VERSION ""

NS_ :

BS_:

BU_: DCDC OBCharger

BO_ 3221225472 VECTOR__INDEPENDENT_SIG_MSG: 0 Vector__XXX
 SG_ DCDC_Protect_Command : 0|2@0+ (1,0) [0|3] "" Vector__XXX

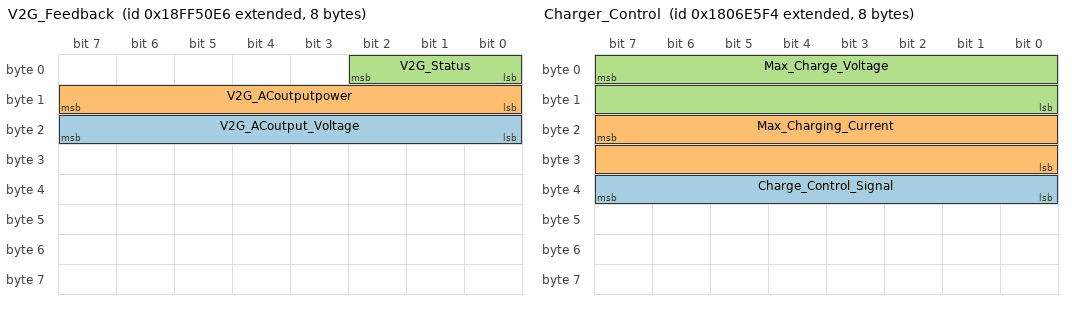
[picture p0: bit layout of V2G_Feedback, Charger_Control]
BO_ 2566869222 V2G_Feedback: 8 OBCharger
 SG_ V2G_ACoutput_Voltage : 23|8@0+ (1,0) [0|255] "V" Vector__XXX
 SG_ V2G_ACoutputpower : 15|8@0+ (0.1,0) [0|25.5] "kw" Vector__XXX
 SG_ V2G_Status : 2|3@0+ (1,0) [0|7] "" Vector__XXX

BO_ 2550588917 V2G_Control: 8 Vector__XXX
 SG_ V2G_Mode : 7|3@0+ (1,0) [0|7] "" Vector__XXX

BO_ 2550173648 DCDC_Control: 8 Vector__XXX
 SG_ DCDC_Control_Command : 1|2@0+ (1,0) [0|3] ""  DCDC

BO_ 2550255759 DCDC_Feedback: 8 DCDC
 SG_ DCDC_Temperature : 63|8@0+ (0.1,0) [0|255] "C" Vector__XXX
 SG_ DCDC_Warm_Temp : 40|1@0+ (1,0) [0|1] "" Vector__XXX
 SG_ DCDC_OverVoltage_outpur : 44|1@0+ (1,0) [0|0] "" Vector__XXX
 SG_ DCDC_OverVoltage_Input : 42|1@0+ (1,0) [0|1] "" Vector__XXX
 SG_ DCDC_Over_Temp : 41|1@0+ (1,0) [0|1] "" Vector__XXX
 SG_ DCDC_LowVoltage_ouptut : 45|1@0+ (1,0) [0|1] "" Vector__XXX
 SG_ DCDC_LowVoltage_input : 43|1@0+ (1,0) [0|1] "" Vector__XXX
 SG_ DCDC_OverCurr_output : 46|1@0+ (1,0) [0|1] "" Vector__XXX
 SG_ DCDC_Ready : 32|1@0+ (1,0) [0|1] "" Vector__XXX
 SG_ DCDC_Status : 33|1@0+ (1,0) [0|1] "" Vector__XXX
 SG_ DCDC_Hard_Fault : 34|1@0+ (1,0) [0|1] "" Vector__XXX
 SG_ DCDC_CAN_error : 35|1@0+ (1,0) [0|255] "" Vector__XXX
 SG_ DCDC_Stop_ERR : 37|1@0+ (1,0) [0|1] "" Vector__XXX
 SG_ DCDC_Fan_control : 36|1@0+ (1,0) [0|1] "" Vector__XXX
 SG_ DCDC_Water_Fan : 38|1@0+ (1,0) [0|1] "" Vector__XXX
 SG_ DCDC_HVIL_ERR : 39|1@0+ (1,0) [0|1] "" Vector__XXX
 SG_ DCDC_Current : 23|16@0+ (0.1,0) [0|65535] "A" Vector__XXX
 SG_ DCDC_Voltage_12V : 7|16@0+ (0.1,0) [0|6553.5] "V" Vector__XXX

BO_ 2550588916 Charger_Control: 8 Vector__XXX
 SG_ Charge_Control_Signal : 39|8@0+ (1,0) [0|0] ""  OBCharger
 SG_ Max_Charging_Current : 23|16@0+ (0.1,0) [0|22.93725] "A"  OBCharger
 SG_ Max_Charge_Voltage : 7|16@0+ (0.1,0) [0|6553.5] "V"  OBCharger

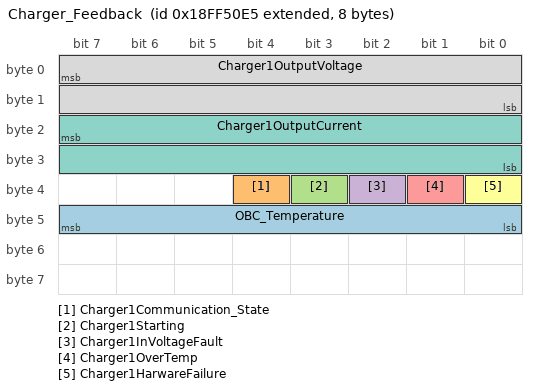
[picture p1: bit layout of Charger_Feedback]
BO_ 2566869221 Charger_Feedback: 8 OBCharger
 SG_ OBC_Temperature : 47|8@0+ (1,0) [0|255] "" Vector__XXX
 SG_ Charger1Communication_State : 36|1@0+ (1,0) [0|1] "" Vector__XXX
 SG_ Charger1Starting : 35|1@0+ (1,0) [0|1] "" Vector__XXX
 SG_ Charger1InVoltageFault : 34|1@0+ (1,0) [0|1] "" Vector__XXX
 SG_ Charger1OverTemp : 33|1@0+ (1,0) [0|1] "" Vector__XXX
 SG_ Charger1HarwareFailure : 32|1@0+ (1,0) [0|1] "" Vector__XXX
 SG_ Charger1OutputCurrent : 23|16@0+ (0.1,0) [0|65.535] "A" Vector__XXX
 SG_ Charger1OutputVoltage : 7|16@0+ (0.1,0) [0|65.535] "V" Vector__XXX

CM_ BO_ 3221225472 "This is a message for not used signals, created by Vector CANdb++ DBC OLE DB Provider.";
BA_DEF_ SG_  "GenSigSendType" ENUM  "Cyclic","OnWrite","OnWriteWithRepetition","OnChange","OnChangeWithRepetition","IfActive","IfActiveWithRepetition","NoSigSendType";
BA_DEF_ SG_  "GenSigILSupport" ENUM  "No","Yes";
BA_DEF_ SG_  "GenSigEVName" STRING ;
BA_DEF_ SG_  "SigType" ENUM  "Default","Range","RangeSigned","ASCII","Discrete","Control","ReferencePGN","DTC","StringDelimiter","StringLength","StringLengthControl";
BA_DEF_ BO_  "VFrameFormat" ENUM  "StandardCAN","ExtendedCAN","reserved","J1939PG";
BA_DEF_ BO_  "GenMsgCycleTime" INT 0 3600000;
BA_DEF_ BO_  "GenMsgRequestable" INT 0 1;
BA_DEF_ BO_  "GenMsgSendType" ENUM  "cyclic","NotUsed","IfActive","NotUsed","NotUsed","NotUsed","NotUsed","NotUsed","noMsgSendType";
BA_DEF_ BO_  "GenMsgILSupport" ENUM  "No","Yes";
BA_DEF_ BU_  "NmStationAddress" INT 0 255;
BA_DEF_ BU_  "NodeLayerModules" STRING ;
BA_DEF_ BU_  "NmAsrCanMsgReducedTime" INT 0 65535;
BA_DEF_ BU_  "NmAsrNode" ENUM  "no","yes";
BA_DEF_  "ProtocolType" STRING ;
BA_DEF_  "DBName" STRING ;
BA_DEF_  "NmAsrBaseAddress" HEX 0 536870911;
BA_DEF_  "NmAsrCanMsgCycleTime" INT 0 65535;
BA_DEF_  "NmAsrMessageCount" INT 0 256;
BA_DEF_  "NmAsrRepeatMessageTime" INT 0 65535;
BA_DEF_  "NmAsrTimeoutTime" INT 0 65535;
BA_DEF_  "NmAsrWaitBusSleepTime" INT 0 65535;
BA_DEF_  "Baudrate" INT 0 10000000;
BA_DEF_  "BusType" STRING ;
BA_DEF_DEF_  "GenSigSendType" "NoSigSendType";
BA_DEF_DEF_  "GenSigILSupport" "Yes";
BA_DEF_DEF_  "GenSigEVName" "Env@Nodename_@Signame";
BA_DEF_DEF_  "SigType" "Default";
BA_DEF_DEF_  "VFrameFormat" "J1939PG";
BA_DEF_DEF_  "GenMsgCycleTime" 0;
BA_DEF_DEF_  "GenMsgRequestable" 1;
BA_DEF_DEF_  "GenMsgSendType" "noMsgSendType";
BA_DEF_DEF_  "GenMsgILSupport" "Yes";
BA_DEF_DEF_  "NmStationAddress" 254;
BA_DEF_DEF_  "NodeLayerModules" "J1939_IL.dll";
BA_DEF_DEF_  "NmAsrCanMsgReducedTime" 50;
BA_DEF_DEF_  "NmAsrNode" "yes";
BA_DEF_DEF_  "ProtocolType" "J1939";
BA_DEF_DEF_  "DBName" "";
BA_DEF_DEF_  "NmAsrBaseAddress" 486506496;
BA_DEF_DEF_  "NmAsrCanMsgCycleTime" 100;
BA_DEF_DEF_  "NmAsrMessageCount" 64;
BA_DEF_DEF_  "NmAsrRepeatMessageTime" 400;
BA_DEF_DEF_  "NmAsrTimeoutTime" 1000;
BA_DEF_DEF_  "NmAsrWaitBusSleepTime" 750;
BA_DEF_DEF_  "Baudrate" 500000;
BA_DEF_DEF_  "BusType" "CAN";
BA_ "ProtocolType" "CAN";
BA_ "DBName" "ZeroEv";
BA_ "NmStationAddress" BU_ DCDC 7;
BA_ "NmStationAddress" BU_ OBCharger 4;
BA_ "VFrameFormat" BO_ 2566869222 1;
BA_ "VFrameFormat" BO_ 2550588917 1;
BA_ "VFrameFormat" BO_ 2550173648 1;
BA_ "VFrameFormat" BO_ 2550255759 1;
BA_ "VFrameFormat" BO_ 2550588916 1;
BA_ "GenMsgSendType" BO_ 2566869221 0;
BA_ "GenMsgCycleTime" BO_ 2566869221 200;
BA_ "VFrameFormat" BO_ 2566869221 1;
VAL_ 3221225472 DCDC_Protect_Command 0 "." 1 "Protection Confirmed" ;
VAL_ 2566869222 V2G_Status 6 "Reserved" 5 "Reserved" 4 "Reserved" 3 "V2VOBC_Enable" 2 "V2LOBC_Enable" 1 "V2GOBC_Enable" 0 "Off" ;
VAL_ 2550588917 V2G_Mode 6 "Reserved" 5 "Reserved" 4 "Reserved" 3 "V2VOBC_Enable" 2 "V2LOBC_Enable" 1 "V2GOBC_Enable" 0 "Off" ;
VAL_ 2550173648 DCDC_Control_Command 2 "Stop" 1 "Start" ;
VAL_ 2550255759 DCDC_Warm_Temp 1 "Temp warning" 0 "Normal Temp" ;
VAL_ 2550255759 DCDC_OverVoltage_outpur 1 "Error" 0 "No Error" ;
VAL_ 2550255759 DCDC_OverVoltage_Input 1 "Error" 0 "No Error" ;
VAL_ 2550255759 DCDC_Over_Temp 1 "Error" 0 "No Error" ;
VAL_ 2550255759 DCDC_LowVoltage_ouptut 1 "Error" 0 "No Error" ;
VAL_ 2550255759 DCDC_LowVoltage_input 1 "Error" 0 "No Error" ;
VAL_ 2550255759 DCDC_OverCurr_output 1 "Error" 0 "No Error" ;
VAL_ 2550255759 DCDC_Ready 1 "Initialization complete" 0 "Initialization uncomplete" ;
VAL_ 2550255759 DCDC_Status 1 "Working" 0 "Not Working" ;
VAL_ 2550255759 DCDC_Hard_Fault 1 "Error" 0 "No Error" ;
VAL_ 2550255759 DCDC_CAN_error 1 "Error" 0 "No Error" ;
VAL_ 2550255759 DCDC_Stop_ERR 1 "Error" 0 "No Error" ;
VAL_ 2550255759 DCDC_Fan_control 1 "Fan ON" 0 "Fan OFF" ;
VAL_ 2550255759 DCDC_Water_Fan 1 "Fan ON" 0 "Fan OFF" ;
VAL_ 2550588916 Charge_Control_Signal 1 "Stop Charging" 0 "Start Charging" ;
VAL_ 2566869221 Charger1Communication_State 1 "Yes" 0 "No" ;
VAL_ 2566869221 Charger1Starting 1 "Error HVBattery not detected" 0 "Charger detected battery" ;
VAL_ 2566869221 Charger1InVoltageFault 1 "Input Voltage Error" 0 "Input Voltage Normal" ;
VAL_ 2566869221 Charger1OverTemp 1 "Over Temperature Protection" 0 "Normal" ;
VAL_ 2566869221 Charger1HarwareFailure 1 "Hardware Failure" 0 "Normal" ;
